# M2354 register map
File version: 1.0
Registers are 32-bit, read-write, reset 0x0 unless marked. A register's access mark holds for its fields unless they carry their own. Offsets are from the block's base; [hi:lo] are bit positions; {n}, {i} and the like mark numbered series; 'fields as' and 'values as' point back to an identical list.

## PRNG_NS — CRYPTO Register Map
Base 0x50032008
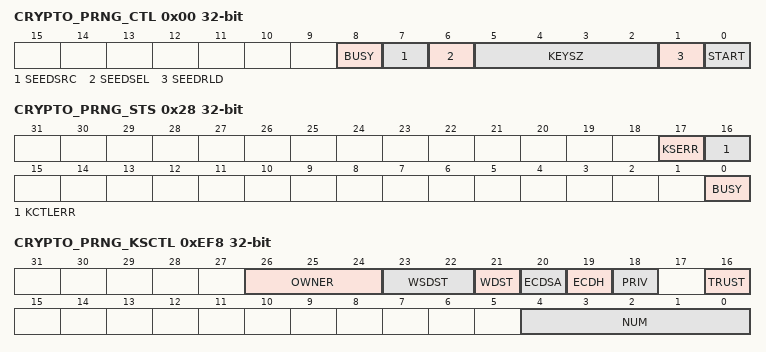
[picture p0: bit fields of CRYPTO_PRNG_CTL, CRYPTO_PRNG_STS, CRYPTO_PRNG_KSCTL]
0x00 CRYPTO_PRNG_CTL — PRNG Control Register
  [8] BUSY ro — PRNG Busy (Read Only)
    0=PRNG engine is idle; 1=Indicate that the PRNG engine is generating CRYPTO_PRNG_KEYx
  [7] SEEDSRC ro — Seed Source (Read Only). Note: This bit is cleared to '0' when SEEDSEL is 0.
    0=Seed is from PRNG; 1=Seed is from TRNG. (not from CRYPTO_PRNG_SEED)
  [6] SEEDSEL — Seed Select. This bit can be set to 1 only after SEEDRDY (TRNG_CTL[9]) bit become to 1.
    0=Select the seed which is from PRNG; 1=Select the seed which is from TRNG (not from CRYPTO_PRNG_SEED)
  [5:2] KEYSZ — PRNG Generate Key Size. Note: 283~571 bits are only generated for Key Store.
    0=128 bits; 1=163 bits; 2=192 bits; 3=224 bits; 4=233 bits; 5=255 bits; 6=256 bits; 7=283 bits (only for KS); 8=384 bits (only for KS); 9=409 bits (only for KS); 10=512 bits (only for KS); 11=521 bits (only for KS); 12=571 bits (only for KS)
  [1] SEEDRLD — Reload New Seed for PRNG Engine
    0=Generating key based on the current seed; 1=Reload new seed
  [0] START — Start PRNG Engine
    0=Stop PRNG engine; 1=Generate new key and store the new key to register CRYPTO_PRNG_KEYx, which will be cleared when the new key is generated
0x04 CRYPTO_PRNG_SEED wo reset not defined — Seed for PRNG
  [31:0] SEED — Seed for PRNG (Write Only). The bits store the seed for PRNG engine. Note: In TRNG+PRNG mode, the seed is from TRNG engine, and it will not be stored in this register.
{0x8+4i} CRYPTO_PRNG_KEY{i} ro reset not defined (i=0..7) — PRNG Generated Key{i}
  [31:0] KEY — Store PRNG Generated Key (Read Only). The bits store the key that is generated by PRNG.
0x28 CRYPTO_PRNG_STS ro — PRNG Status Register
  [17] KSERR — PRNG Access Key Store Error Flag
    0=No error; 1=Access key store fail
  [16] KCTLERR — PRNG Key Control Register Error Flag
    0=No error; 1=PRNG key control error. When PRNG execute ECDSA or ECDH, but PRNG seed not from TRNG or key is not written to the SRAM of key store (WSDST, CRYPTO_PRNG_KSCTL[23:22] is not equal to '00')
  [0] BUSY — PRNG Busy Flag
    values as CRYPTO_PRNG_CTL.BUSY
0xEF8 CRYPTO_PRNG_KSCTL wo — PRNG Key Control Register
  [26:24] OWNER — Write Key Owner Selection Bits
    0=Only for AES use; 1=Only for HMAC engine use; 4=Only for ECC engine use; 5=Only for CPU engine use
  [23:22] WSDST — Write Key Store Destination
    0=Key is written to the SRAM of key store; 2=Key is written to the OTP of key store
  [21] WDST — Write Key Destination
    0=Key is written to registers CRYPTO_PRNG_KEYx; 1=Key is written to key store
  [20] ECDSA — ECDSA Control Bit. Note: When ECDSA is set to '1', 1. PRNG seed must come from TRNG and key must be written to the SRAM of key store (WSDST, CRYPTO_PRNG_KSCTL[23:22] must set to '00'). Otherwise, KCTLERR will become '1'(CRYPTO_PRNG_KSSTS[16]). 2. Key must be in the interval [1, n-1] (the parameter n is from ECC). The value of n cannot be 0 or 1; otherwise, PRNG will always keep busy.
    1=Key is written to key store and used in ECDSA
  [19] ECDH — ECDH Control Bit. Note: When ECDH is set to '1', 1. PRNG seed must come from TRNG and key must be written to the SRAM of key store (WSDST, CRYPTO_PRNG_KSCTL[23:22] must set to '00'). Otherwise, KCTLERR will become '1'(CRYPTO_PRNG_KSSTS[16]).2. Key must be in the interval [1, n-1] (the parameter n is from ECC). The value of n cannot be 0 or 1; otherwise, PRNG will always keep busy.
    1=Key is written to key store and used in ECDH
  [18] PRIV — Privilege Key Selection Bit
    0=Set key as the non-privilege key; 1=Set key as the privilege key
  [16] TRUST — Write Key Trust Selection Bit
    0=Set written key as the non-secure key; 1=Set written key as the secure key
  [4:0] NUM — Write Key Number. The key number is sent to key store. Note: Only for destination is OTP of Key Store.
0xEFC CRYPTO_PRNG_KSSTS ro — PRNG Key Status Register
  [4:0] NUM — Key Number. The key number is generated by key store
